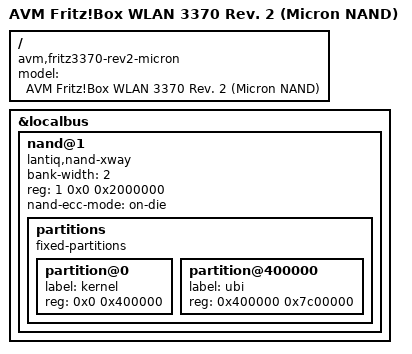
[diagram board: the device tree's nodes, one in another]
/dts-v1/;

#include "FRITZ3370-REV2.dtsi"

/ {
	compatible = "avm,fritz3370-rev2-micron", "avm,fritz3370-rev2", "lantiq,xway", "lantiq,vr9";
	model = "AVM Fritz!Box WLAN 3370 Rev. 2 (Micron NAND)";
};

&localbus {
	nand@1 {
		compatible = "lantiq,nand-xway";
		bank-width = <2>;
		reg = <1 0x0 0x2000000>;
		#address-cells = <1>;
		#size-cells = <1>;

		nand-ecc-mode = "on-die";

		partitions {
			compatible = "fixed-partitions";
			#address-cells = <1>;
			#size-cells = <1>;

			partition@0 {
				label = "kernel";
				reg = <0x0 0x400000>;
			};

			partition@400000 {
				label = "ubi";
				reg = <0x400000 0x7c00000>;
			};
		};
	};
};
